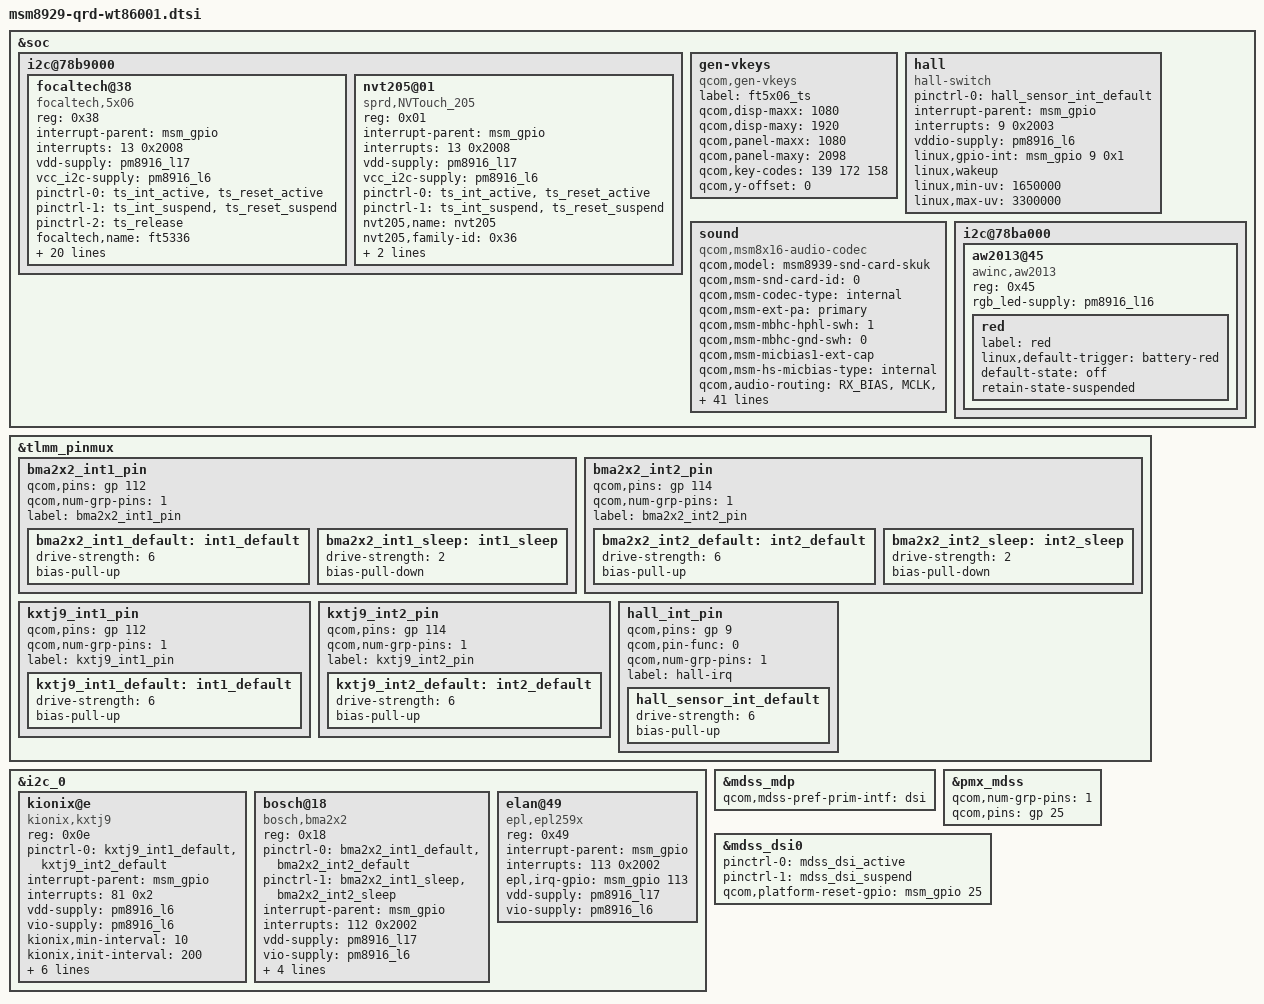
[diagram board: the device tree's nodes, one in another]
/* Copyright (c) 2014-2015, The Linux Foundation. All rights reserved.
 *
 * This program is free software; you can redistribute it and/or modify
 * it under the terms of the GNU General Public License version 2 and
 * only version 2 as published by the Free Software Foundation.
 *
 * This program is distributed in the hope that it will be useful,
 * but WITHOUT ANY WARRANTY; without even the implied warranty of
 * MERCHANTABILITY or FITNESS FOR A PARTICULAR PURPOSE.  See the
 * GNU General Public License for more details.
 */

#include "msm8939-qrd.dtsi"
#include "msm8939-camera-sensor-qrd.dtsi"

&soc {
	i2c@78b9000 { /* BLSP1 QUP5 */
		focaltech@38 {
			compatible = "focaltech,5x06";
			reg = <0x38>;
			interrupt-parent = <&msm_gpio>;
			interrupts = <13 0x2008>;
			vdd-supply = <&pm8916_l17>;
			vcc_i2c-supply = <&pm8916_l6>;
			/* pins used by touchscreen */
			pinctrl-names = "pmx_ts_active","pmx_ts_suspend","pmx_ts_release";
			pinctrl-0 = <&ts_int_active &ts_reset_active>;
			pinctrl-1 = <&ts_int_suspend &ts_reset_suspend>;
			pinctrl-2 = <&ts_release>;
			focaltech,name = "ft5336";
			focaltech,family-id = <0x14>;
			focaltech,reset-gpio = <&msm_gpio 12 0x0>;
			focaltech,irq-gpio = <&msm_gpio 13 0x2008>;
			focaltech,display-coords = <0 0 1080 1920>;
			focaltech,panel-coords = <0 0 1080 2098>;
			focaltech,button-map= <139 102 158>;
			focaltech,no-force-update;
			focaltech,i2c-pull-up;
			focaltech,group-id = <1>;
			focaltech,hard-reset-delay-ms = <20>;
			focaltech,soft-reset-delay-ms = <200>;
			focaltech,num-max-touches = <5>;
			focaltech,fw-delay-aa-ms = <30>;
			focaltech,fw-delay-55-ms = <30>;
			focaltech,fw-upgrade-id1 = <0x11>;
			focaltech,fw-upgrade-id2 = <0x11>;
			focaltech,fw-delay-readid-ms = <10>;
			focaltech,fw-delay-era-flsh-ms = <2000>;
			focaltech,fw-auto-cal;
			focaltech,ignore-id-check;
		};

		nvt205@01 {
			compatible = "sprd,NVTouch_205";
			reg = <0x01>;
			interrupt-parent = <&msm_gpio>;
			interrupts = <13 0x2008>;
			vdd-supply = <&pm8916_l17>;
			vcc_i2c-supply = <&pm8916_l6>;
			/* pins used by touchscreen */
			pinctrl-names = "pmx_ts_active","pmx_ts_suspend";
			pinctrl-0 = <&ts_int_active &ts_reset_active>;
			pinctrl-1 = <&ts_int_suspend &ts_reset_suspend>;
			nvt205,name = "nvt205";
			nvt205,family-id = <0x36>;
			nvt205,reset-gpio = <&msm_gpio 12 0x0>;
			nvt205,irq-gpio = <&msm_gpio 13 0x2008>;
			
			};
	};

	gen-vkeys {
		compatible = "qcom,gen-vkeys";
		label = "ft5x06_ts";
		qcom,disp-maxx = <1080>;
		qcom,disp-maxy = <1920>;
		qcom,panel-maxx = <1080>;
		qcom,panel-maxy = <2098>;
		qcom,key-codes = <139 172 158>;
		qcom,y-offset = <0>;
	};

	hall {
		compatible = "hall-switch";
		pinctrl-names = "default";
		pinctrl-0 = <&hall_sensor_int_default>;
		interrupt-parent = <&msm_gpio>;
		interrupts = <9 0x2003>;
		vddio-supply = <&pm8916_l6>;
		linux,gpio-int = <&msm_gpio 9 0x1>;
		linux,wakeup;
		linux,min-uv = <1650000>;
		linux,max-uv = <3300000>;
	};

	sound {
		compatible = "qcom,msm8x16-audio-codec";
		qcom,model = "msm8939-snd-card-skuk";
		qcom,msm-snd-card-id = <0>;
		qcom,msm-codec-type = "internal";
		qcom,msm-ext-pa = "primary";
		qcom,msm-mbhc-hphl-swh = <1>;
		qcom,msm-mbhc-gnd-swh = <0>;
		qcom,msm-micbias1-ext-cap;
		qcom,msm-hs-micbias-type = "internal";
		qcom,audio-routing =
			"RX_BIAS", "MCLK",
			"SPK_RX_BIAS", "MCLK",
			"INT_LDO_H", "MCLK",
			"MIC BIAS External", "Handset Mic",
			"MIC BIAS Internal2", "Headset Mic",
			"MIC BIAS External", "Secondary Mic",
			"AMIC1", "MIC BIAS External",
			"AMIC2", "MIC BIAS Internal2",
			"AMIC3", "MIC BIAS External";
		pinctrl-names = "cdc_lines_act",
				"cdc_lines_sus";
		pinctrl-0 = <&cdc_pdm_lines_act>;
		pinctrl-1 = <&cdc_pdm_lines_sus>;
		asoc-platform = <&pcm0>, <&pcm1>, <&voip>, <&voice>,
				<&loopback>, <&compress>, <&hostless>,
				<&afe>, <&lsm>, <&routing>, <&lpa>;
		asoc-platform-names = "msm-pcm-dsp.0", "msm-pcm-dsp.1",
				"msm-voip-dsp", "msm-pcm-voice", "msm-pcm-loopback",
				"msm-compress-dsp", "msm-pcm-hostless", "msm-pcm-afe",
				"msm-lsm-client", "msm-pcm-routing", "msm-pcm-lpa";
		asoc-cpu = <&dai_pri_auxpcm>, <&dai_hdmi>, <&dai_mi2s0>, <&dai_mi2s1>,
				<&dai_mi2s2>, <&dai_mi2s3>, <&sb_0_rx>, <&sb_0_tx>,
				<&sb_1_rx>, <&sb_1_tx>, <&sb_3_rx>, <&sb_3_tx>,
				<&sb_4_rx>, <&sb_4_tx>, <&sb_5_tx>, <&bt_sco_rx>,
				<&bt_sco_tx>, <&int_fm_rx>, <&int_fm_tx>, <&afe_pcm_rx>,
				<&afe_pcm_tx>, <&afe_proxy_rx>, <&afe_proxy_tx>,
				<&incall_record_rx>, <&incall_record_tx>, <&incall_music_rx>,
				<&incall_music_2_rx>;
		asoc-cpu-names = "msm-dai-q6-auxpcm.1", "msm-dai-q6-hdmi.8", "msm-dai-q6-mi2s.0",
				"msm-dai-q6-mi2s.1", "msm-dai-q6-mi2s.2",
				"msm-dai-q6-mi2s.3", "msm-dai-q6-dev.16384",
				"msm-dai-q6-dev.16385", "msm-dai-q6-dev.16386",
				"msm-dai-q6-dev.16387", "msm-dai-q6-dev.16390",
				"msm-dai-q6-dev.16391", "msm-dai-q6-dev.16392",
				"msm-dai-q6-dev.16393", "msm-dai-q6-dev.16395",
				"msm-dai-q6-dev.12288", "msm-dai-q6-dev.12289",
				"msm-dai-q6-dev.12292", "msm-dai-q6-dev.12293",
				"msm-dai-q6-dev.224", "msm-dai-q6-dev.225",
				"msm-dai-q6-dev.241", "msm-dai-q6-dev.240",
				"msm-dai-q6-dev.32771", "msm-dai-q6-dev.32772",
				"msm-dai-q6-dev.32773", "msm-dai-q6-dev.32770";
		asoc-codec = <&stub_codec>, <&pm8916_tombak_dig>;
		asoc-codec-names = "msm-stub-codec.1", "tombak_codec";
	};
i2c@78ba000 { /* i2c 6 */
	aw2013@45 { /*blink */
		compatible = "awinc,aw2013";
		reg = <0x45>;
		rgb_led-supply = <&pm8916_l16>;
		
		red {
			label = "red";
			linux,default-trigger = "battery-red";
			default-state = "off";
			retain-state-suspended;
		};

	};
};
};


&tlmm_pinmux {
	bma2x2_int1_pin {
		qcom,pins = <&gp 112>;
		qcom,num-grp-pins = <1>;
		label = "bma2x2_int1_pin";
		bma2x2_int1_default: int1_default {
			  drive-strength = <6>;
			  bias-pull-up;
		};
		bma2x2_int1_sleep: int1_sleep {
			  drive-strength = <2>;
			  bias-pull-down;
		};
	};

	bma2x2_int2_pin {
		qcom,pins = <&gp 114>;
		qcom,num-grp-pins = <1>;
		label = "bma2x2_int2_pin";
		bma2x2_int2_default: int2_default {
			  drive-strength = <6>;
			  bias-pull-up;
		};
		bma2x2_int2_sleep: int2_sleep {
			  drive-strength = <2>;
			  bias-pull-down;
		};
	};

	kxtj9_int1_pin {
		qcom,pins = <&gp 112>;
		qcom,num-grp-pins = <1>;
		label = "kxtj9_int1_pin";
		kxtj9_int1_default: int1_default {
			  drive-strength = <6>;
			  bias-pull-up;
		};
	};
	kxtj9_int2_pin {
		qcom,pins = <&gp 114>;
		qcom,num-grp-pins = <1>;
		label = "kxtj9_int2_pin";
		kxtj9_int2_default: int2_default {
			  drive-strength = <6>;
			  bias-pull-up;
		};
	};
	/*epl259x_int_pin {
		qcom,pins = <&gp 113>;
		qcom,pin-func = <0>;
		qcom,num-grp-pins = <1>;
		label = "epl259x-irq";
		epl259x_default: epl259x_default {
		drive-strength = <6>;
		bias-pull-up;
		};
	};*/

	hall_int_pin {
		qcom,pins = <&gp 9>;
		qcom,pin-func = <0>;
		qcom,num-grp-pins = <1>;
		label = "hall-irq";
		hall_sensor_int_default: hall_sensor_int_default {
			drive-strength = <6>;
			bias-pull-up;
		};
	};
};

&i2c_0 { /* BLSP1 QUP2 */
	kionix@e {
	       compatible = "kionix,kxtj9";
		reg = <0x0e>;
		pinctrl-names = "default";
		pinctrl-0 = <&kxtj9_int1_default &kxtj9_int2_default>;
		interrupt-parent = <&msm_gpio>;
		interrupts = <81 0x2>;
		vdd-supply = <&pm8916_l6>;
		vio-supply = <&pm8916_l6>;
		kionix,min-interval = <10>;
		kionix,init-interval = <200>;
		kionix,axis-map-x = <1>;
		kionix,axis-map-y = <0>;
		kionix,axis-map-z = <2>;
		kionix,g-range = <2>;
		kionix,negate-z;
		kionix,res-12bit;
	 };



	bosch@18 { /* Accelerometer sensor */
		compatible = "bosch,bma2x2";
		reg = <0x18>;
		pinctrl-names = "bma_default","bma_sleep";
		pinctrl-0 = <&bma2x2_int1_default &bma2x2_int2_default>;
		pinctrl-1 = <&bma2x2_int1_sleep &bma2x2_int2_sleep>;
		interrupt-parent = <&msm_gpio>;
		interrupts = <112 0x2002>;
		vdd-supply = <&pm8916_l17>;
		vio-supply = <&pm8916_l6>;
		bosch,init-interval = <200>;
		bosch,place = <2>;
		bosch,gpio-int1 = <&msm_gpio 112 0x2002>;
		bosch,gpio-int2 = <&msm_gpio 114 0x2002>;
	};

/*

	senodia@c {
		compatible = "senodia,st480";
		reg = <0xc>;
		vdd-supply = <&pm8916_l17>;
		vio-supply = <&pm8916_l6>;
	};

*/

	/*elan@23 {
		compatible = "epl,epl259x";
		reg = <0x23>;
		pinctrl-names = "default";
		pinctrl-0 = <&epl259x_default>;
		interrupt-parent = <&msm_gpio>;
		interrupts = <113 0x2002>;
		vdd-supply = <&pm8916_l17>;
		vio-supply = <&pm8916_l6>;
		epl2182,irq-gpio = <&msm_gpio 113 0x2002>;
		epl2182,prox_th_min = <1900>;
		epl2182,prox_th_max = <2600>;
	};*/
	elan@49 {
		reg = <0x49>;
		compatible = "epl,epl259x";
		interrupt-parent = <&msm_gpio>;
		interrupts = <113 0x2002>;
		epl,irq-gpio  = <&msm_gpio 113 0x2002>;
		vdd-supply = <&pm8916_l17>;
		vio-supply = <&pm8916_l6>;
	};
};




&mdss_mdp {
	qcom,mdss-pref-prim-intf = "dsi";
};

&pmx_mdss {
	qcom,num-grp-pins = <1>;
	qcom,pins = <&gp 25>;
};

&mdss_dsi0 {
	pinctrl-names = "mdss_default", "mdss_sleep";
	pinctrl-0 = <&mdss_dsi_active>;
	pinctrl-1 = <&mdss_dsi_suspend>;

	qcom,platform-reset-gpio = <&msm_gpio 25 0>;
//	qcom,platform-bklight-en-gpio = <&msm_gpio 1 0>;
};

